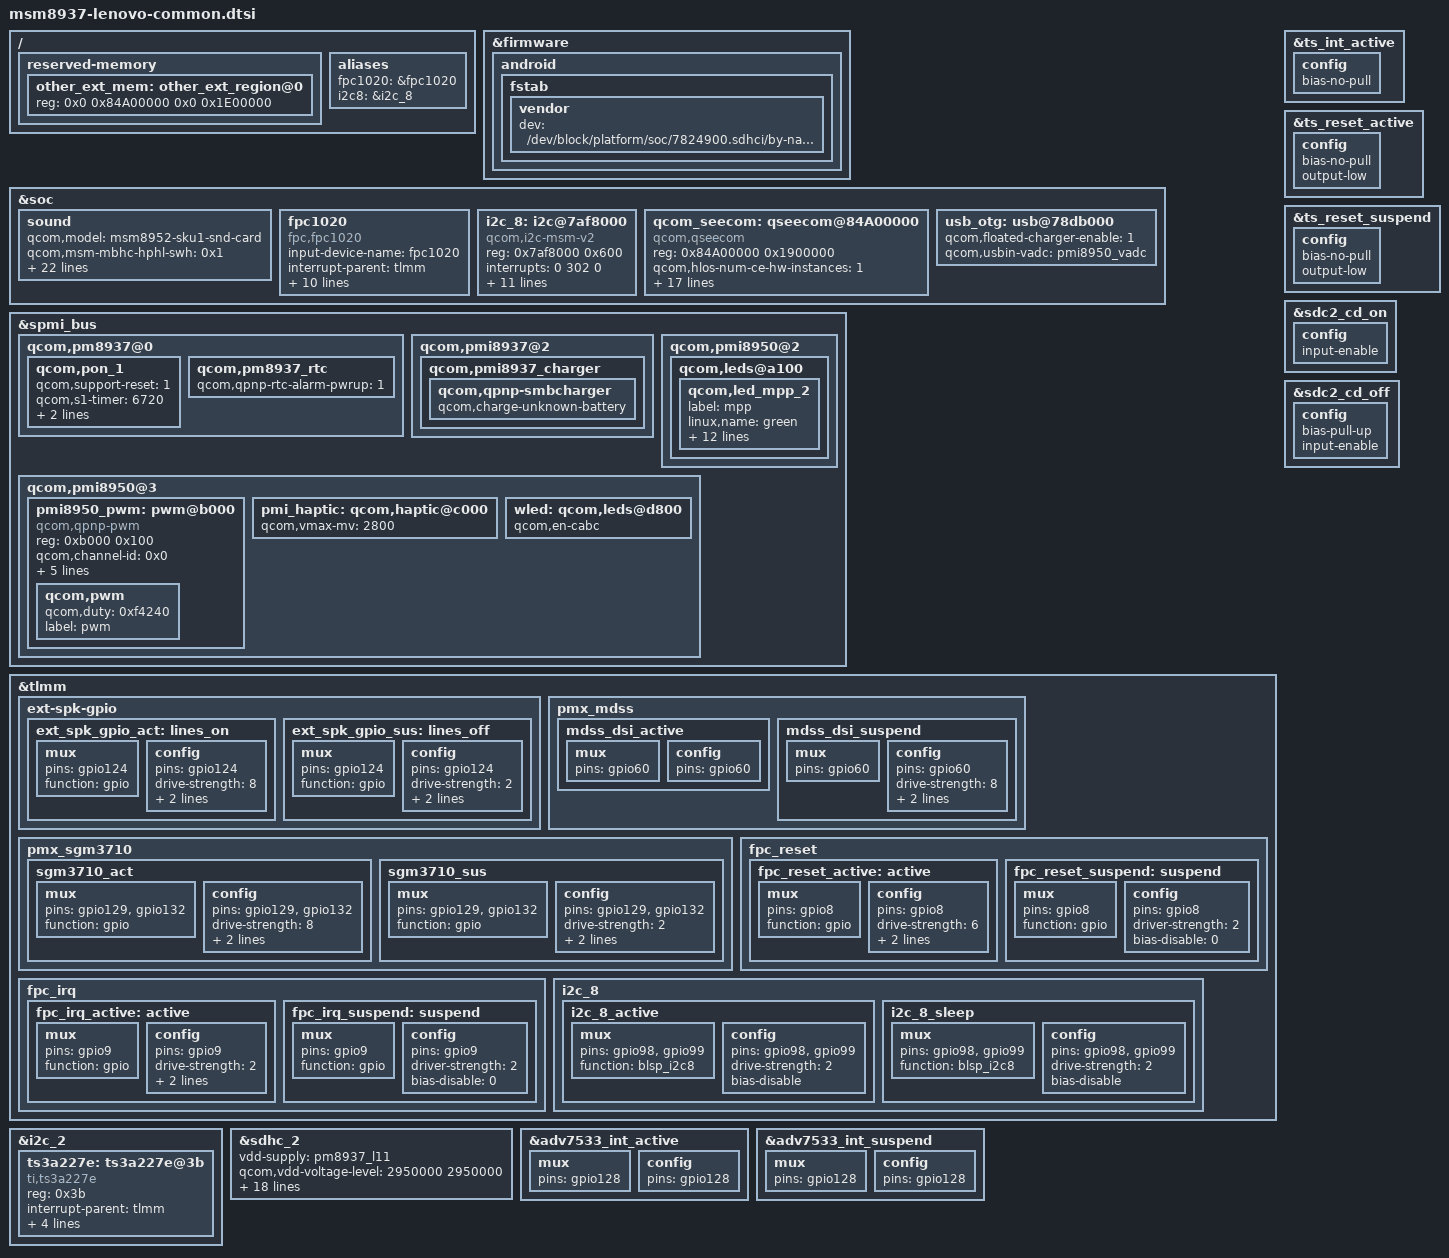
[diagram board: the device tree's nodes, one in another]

/*
 * Copyright (c) 2015, The lenovo mobile Inc. All rights reserved.
 *
 * This program is free software; you can redistribute it and/or modify
 * it under the terms of the GNU General Public License version 2 and
 * only version 2 as published by the Free Software Foundation.
 *
 * This program is distributed in the hope that it will be useful,
 * but WITHOUT ANY WARRANTY; without even the implied warranty of
 * MERCHANTABILITY or FITNESS FOR A PARTICULAR PURPOSE.  See the
 * GNU General Public License for more details.
 */


#include "../msm8937.dtsi"
#include "../msm8937-pmi8950-qrd-sku1.dtsi"

/ {

	reserved-memory {
		other_ext_mem: other_ext_region@0 {
			reg = <0x0 0x84A00000 0x0 0x1E00000>;
		};
	};

	aliases {
		fpc1020 = &fpc1020;
		i2c8 = &i2c_8;
	};
};

&firmware {
	android {
		fstab {
			vendor {
				dev = "/dev/block/platform/soc/7824900.sdhci/by-name/preload";
			};
		};
	};
};

&soc {
	sound {
		qcom,model = "msm8952-sku1-snd-card";
		qcom,msm-mbhc-hphl-swh = <0x1>;
		qcom,msm-mbhc-gnd-swh = <0x1>;
		qcom,msm-hs-micbias-type = "internal";
		qcom,msm-spk-ext-pa = <&tlmm 124 0>;
		qcom,msm-hs-ext-rbias;
		qcom,msm-gpios =
			"pri_i2s",
			"ext_spk_gpio";
		qcom,pinctrl-names =
			"all_off",
			"pri_i2s_act",
			"ext_spk_gpio_act",
			"pri_i2s_ext_spk_act";
		pinctrl-names =
			"all_off",
			"pri_i2s_act",
			"ext_spk_gpio_act",
			"pri_i2s_ext_spk_act";
		pinctrl-0 = <&cdc_pdm_lines_sus
				&cdc_pdm_lines_2_sus &ext_spk_gpio_sus>;
		pinctrl-1 = <&cdc_pdm_lines_act
				&cdc_pdm_lines_2_act &ext_spk_gpio_sus>;
		pinctrl-2 = <&cdc_pdm_lines_sus
				&cdc_pdm_lines_2_sus &ext_spk_gpio_act>;
		pinctrl-3 = <&cdc_pdm_lines_act
				&cdc_pdm_lines_2_act &ext_spk_gpio_act>;
		qcom,audio-routing =
			"RX_BIAS", "MCLK",
			"SPK_RX_BIAS", "MCLK",
			"INT_LDO_H", "MCLK",
			"MIC BIAS External", "Handset Mic",
			"MIC BIAS Internal2", "Headset Mic",
			"MIC BIAS External", "Secondary Mic",
			"AMIC1", "MIC BIAS External",
			"AMIC2", "MIC BIAS Internal2",
			"AMIC3", "MIC BIAS External";
	};

	fpc1020: fpc1020 {
		status = "ok";
		compatible = "fpc,fpc1020";
		input-device-name = "fpc1020";
		interrupt-parent = <&tlmm>;
		interrupts = <9 0x0>;
		fpc,reset-gpio  = <&tlmm 8 0x2>;
		fpc,irq-gpio    = <&tlmm 9 0x1>;
		pinctrl-names = "pmx_fp_active", "pmx_fp_suspend";
		pinctrl-0 = <&fpc_reset_active &fpc_irq_active>;
		pinctrl-1 = <&fpc_reset_suspend &fpc_irq_suspend>;

		vcc_spi-supply  = <&pm8937_l5>;
		vdd_ana-supply  = <&pm8937_l5>;
		vdd_io-supply   = <&pm8937_l5>;
		/* fpc,enable-on-boot; */
		clock-names = "iface_clk", "core_clk";
		clocks = <&clock_gcc clk_gcc_blsp2_ahb_clk>,
			<&clock_gcc clk_gcc_blsp2_qup2_spi_apps_clk>;
	};

	i2c_8: i2c@7af8000 { /* BLSP2 QUP4 */
		compatible = "qcom,i2c-msm-v2";
		#address-cells = <1>;
		#size-cells = <0>;
		reg-names = "qup_phys_addr";
		reg = <0x7af8000 0x600>;
		interrupt-names = "qup_irq";
		interrupts = <0 302 0>;
		qcom,clk-freq-out = <400000>;
		qcom,clk-freq-in  = <19200000>;
		clock-names = "iface_clk", "core_clk";
		clocks = <&clock_gcc clk_gcc_blsp2_ahb_clk>,
			 <&clock_gcc clk_gcc_blsp2_qup4_i2c_apps_clk>;

		pinctrl-names = "i2c_active", "i2c_sleep";
		pinctrl-0 = <&i2c_8_active>;
		pinctrl-1 = <&i2c_8_sleep>;
		qcom,noise-rjct-scl = <0>;
		qcom,noise-rjct-sda = <0>;
		qcom,master-id = <84>;
		dmas = <&dma_blsp2 10 64 0x20000020 0x20>,
			<&dma_blsp2 11 32 0x20000020 0x20>;
		dma-names = "tx", "rx";
	};

	/delete-node/ qseecom@85b00000;

	qcom_seecom: qseecom@84A00000 {
		compatible = "qcom,qseecom";
		reg = <0x84A00000 0x1900000>;
		reg-names = "secapp-region";
		qcom,hlos-num-ce-hw-instances = <1>;
		qcom,hlos-ce-hw-instance = <0>;
		qcom,qsee-ce-hw-instance = <0>;
		qcom,disk-encrypt-pipe-pair = <2>;
		qcom,support-fde;
		qcom,appsbl-qseecom-support;
		qcom,msm-bus,name = "qseecom-noc";
		qcom,msm-bus,num-cases = <4>;
		qcom,msm-bus,num-paths = <1>;
		qcom,support-bus-scaling;
		qcom,msm-bus,vectors-KBps =
			<55 512 0 0>,
			<55 512 0 0>,
			<55 512 120000 1200000>,
			<55 512 393600 3936000>;
		clocks = <&clock_gcc clk_crypto_clk_src>,
			 <&clock_gcc clk_gcc_crypto_clk>,
			 <&clock_gcc clk_gcc_crypto_ahb_clk>,
			 <&clock_gcc clk_gcc_crypto_axi_clk>;
		clock-names = "core_clk_src", "core_clk",
				"iface_clk", "bus_clk";
		qcom,ce-opp-freq = <100000000>;
	};

	usb_otg: usb@78db000 {
                qcom,floated-charger-enable = <1>;
        };
};

&spmi_bus {
	qcom,pm8937@0 {
		qcom,pon_1 {
				qcom,support-reset = <1>;
				qcom,s1-timer = <6720>;
				qcom,s2-timer = <2000>;
				qcom,s2-type = <7>;
                        };

		qcom,pm8937_rtc {
			        qcom,qpnp-rtc-alarm-pwrup = <1>;
                        };
                };

	qcom,pmi8937@2 {
                qcom,pmi8937_charger {
                        qcom,qpnp-smbcharger {
                                qcom,charge-unknown-battery;
                        };
                };
        };

	qcom,pmi8950@2 {
		qcom,leds@a100 {
			status = "okay";
			qcom,led_mpp_2 {
				label = "mpp";
				linux,name = "green";
				linux,default-trigger = "none";
				qcom,default-state = "off";
				qcom,max-current = <0x5>;
				qcom,current-setting = <0x5>;
				qcom,id = <0x6>;
				qcom,mode = "pwm";
				qcom,pwm-channel = <0x0>;
				pwms = <0x11b 0x0 0x0>;
				pwm-names = "green";
				qcom,source-sel = <0x8>;
				qcom,pwm-us = <0x3e8>;
				qcom,mode-ctrl = <0x60>;
			};
		};
	};

        qcom,pmi8950@3 {
                         pmi8950_pwm: pwm@b000{
				status = "okay";
				compatible = "qcom,qpnp-pwm";
				reg = <0xb000 0x100>;
				reg-names = "qpnp-lpg-channel-base";
				qcom,channel-id = <0x0>;
				qcom,supported-sizes = <0x6 0x9>;
				#pwm-cells = <0x2>;
				qcom,period = <0x1e8480>;
				qcom,mode-select = <0x0>;
				qcom,dtest-output = <0x1>;
				qcom,dtest-line = <0x1>;
				linux,phandle = <0x11b>;
				phandle = <0x11b>;

				qcom,pwm {
					qcom,duty = <0xf4240>;
					label = "pwm";
			};
		};

		pmi_haptic: qcom,haptic@c000 {
                                qcom,vmax-mv = <2800>;
                };

		wled: qcom,leds@d800 {
			        qcom,en-cabc;
                                /delete-property/ qcom,en-ext-pfet-sc-pro;
                };
	};
};

&tlmm {
	ext-spk-gpio {
		ext_spk_gpio_act: lines_on {
			mux {
				pins = "gpio124";
				function = "gpio";
			};

			config {
				pins = "gpio124";
				drive-strength = <8>;
				output-high;
				bias-disable;
			};
		};

		ext_spk_gpio_sus: lines_off {
			mux {
				pins = "gpio124";
				function = "gpio";
			};

			config {
				pins = "gpio124";
				drive-strength = <2>;
				output-low;
				bias-disable;
			};
		};
	};

	pmx_mdss: pmx_mdss {
		mdss_dsi_active: mdss_dsi_active {
			mux {
				pins = "gpio60";
			};
			config {
				pins = "gpio60";
			};
		};

		mdss_dsi_suspend: mdss_dsi_suspend {
			mux {
				pins = "gpio60";
			};
			config {
				pins = "gpio60";
                                drive-strength = <8>;
                                bias-disable = <0>;
                                output-high;
			};
		};
	};

	pmx_sgm3710 {
		sgm3710_act: sgm3710_act {
			mux {
				pins = "gpio129", "gpio132";
				function = "gpio";
			};

			config {
				pins = "gpio129", "gpio132";
				drive-strength = <8>;
				output-high;
				bias-disable;
			};
		};

		sgm3710_sus: sgm3710_sus {
			mux {
				pins = "gpio129", "gpio132";
				function = "gpio";
			};

			config {
				pins = "gpio129", "gpio132";
				drive-strength = <2>;
				output-low;
				bias-disable;
			};
		};
	};
};

&i2c_2 {
	ts3a227e: ts3a227e@3b {
		compatible = "ti,ts3a227e";
		reg = <0x3b>;
		interrupt-parent = <&tlmm>;
		interrupts = <25 0x0>;
		ti,fm_support;
		pinctrl-names = "pmx_hp_switch_on",
			"pmx_hp_switch_off";
		pinctrl-0 = <&sgm3710_act>;
		pinctrl-1 = <&sgm3710_sus>;
	};
};

&sdhc_2 {
	/* device core power supply */
	vdd-supply = <&pm8937_l11>;
	qcom,vdd-voltage-level = <2950000 2950000>;
	qcom,vdd-current-level = <15000 800000>;

	/* device communication power supply */
	vdd-io-supply = <&pm8937_l12>;
	qcom,vdd-io-voltage-level = <1800000 2950000>;
	qcom,vdd-io-current-level = <200 22000>;

	pinctrl-names = "active", "sleep";
	pinctrl-0 = <&sdc2_clk_on &sdc2_cmd_on &sdc2_data_on &sdc2_cd_on>;
	pinctrl-1 = <&sdc2_clk_off &sdc2_cmd_off &sdc2_data_off &sdc2_cd_off>;

	#address-cells = <0>;
	interrupt-parent = <&sdhc_2>;
	interrupts = <0 1 2>;
	#interrupt-cells = <1>;
	interrupt-map-mask = <0xffffffff>;
	interrupt-map = <0 &intc 0 125 0
		1 &intc 0 221 0
		2 &tlmm 67 0>;
	interrupt-names = "hc_irq", "pwr_irq", "status_irq";
	cd-gpios = <&tlmm 67 0x1>;

	qcom,clk-rates = <400000 20000000 25000000 50000000 100000000
								200000000>;
	qcom,bus-speed-mode = "SDR12", "SDR25", "SDR50", "DDR50", "SDR104";

	status = "ok";
};

&tlmm {
	fpc_reset {
		fpc_reset_active: active {
			mux {
				pins = "gpio8";
				function = "gpio";
			};

			config {
				pins = "gpio8";
				drive-strength = <6>;
				bias-disable = <0>;
				output-high;
			};
		};
		fpc_reset_suspend: suspend {
			mux {
				pins = "gpio8";
				function = "gpio";
			};

			config {
				pins = "gpio8";
				driver-strength = <2>;
				bias-disable = <0>;
			};
		};
	};

	fpc_irq {
		fpc_irq_active: active {
			mux {
				pins = "gpio9";
				function = "gpio";
			};

			config {
				pins = "gpio9";
				drive-strength = <2>;
				bias-disable = <0>;
				input-enable;
			};
		};
		fpc_irq_suspend: suspend {
			mux {
				pins = "gpio9";
				function = "gpio";
			};

			config {
				pins = "gpio9";
				driver-strength = <2>;
				bias-disable = <0>;
			};
		};
	};

        i2c_8 {
                       /* active state */
               i2c_8_active: i2c_8_active{
                       mux {
                               /* CLK, DATA */
                               pins = "gpio98", "gpio99";
                               function = "blsp_i2c8";
                       };

                       config {
                               pins = "gpio98", "gpio99";
                               drive-strength = <2>; /* 2 MA */
                               bias-disable; /* No PULL */
                       };
               };

                       /* suspended state */
               i2c_8_sleep: i2c_8_sleep {
                       mux {
                               /* CLK, DATA */
                               pins = "gpio98", "gpio99";
                               function = "blsp_i2c8";
                       };

                       config {
                               pins = "gpio98", "gpio99";
                               drive-strength = <2>; /* 2 MA */
                               bias-disable; /* No PULL */
                       };
               };
       };
};

&adv7533_int_active {
                       mux {
                               pins = "gpio128";
                       };
                       config {
                               pins = "gpio128";
                       };
                };

&adv7533_int_suspend {
                       mux {
                               pins = "gpio128";
                       };
                       config {
                               pins = "gpio128";
                       };
                };

&ts_int_active {
                       config {
                               /delete-property/ bias-pull-up;
                               bias-no-pull;
                       };
                };

&ts_reset_active {
                       config {
                               /delete-property/ bias-pull-up;
                               bias-no-pull;
                               output-low;
                       };
                };

&ts_reset_suspend {
                       config {
                               /delete-property/ bias-pull-up;
                               bias-no-pull;
                               output-low;
                       };
                };

&sdc2_cd_on {
                       config {
                               input-enable;
                       };
                };

&sdc2_cd_off {
                       config {
                               /delete-property/ bias-disable;
                               bias-pull-up;
                               input-enable;
                       };
                };

&usb_otg {
                qcom,usbin-vadc = <&pmi8950_vadc>;
        };
